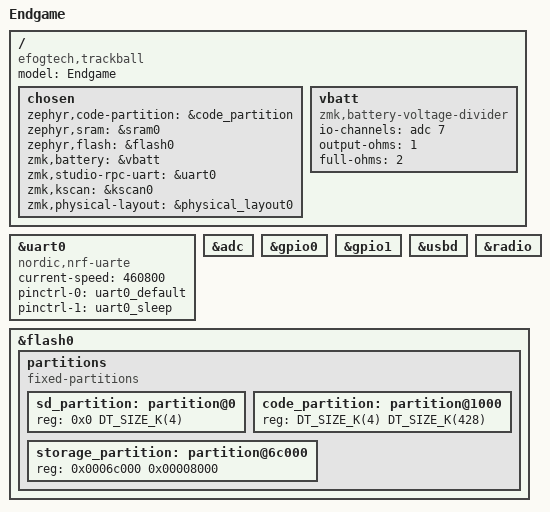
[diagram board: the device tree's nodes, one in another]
/dts-v1/;
#include <nordic/nrf52833_qiaa.dtsi>
#include <dt-bindings/zmk/input_transform.h>
#include <dt-bindings/zmk/matrix_transform.h>
#include <physical_layouts.dtsi>
#include <zephyr/dt-bindings/input/input-event-codes.h>
#include <input/processors.dtsi>
#include <dt-bindings/led/led.h>
#include "buttons.dtsi"
#include "behaviors_macros.dtsi"
#include "pinctrl.dtsi"
#include "pointer.dtsi"
#include "encoders.dtsi"
#include "visuals.dtsi"

/ {
    model = "Endgame";
    compatible = "efogtech,trackball";

    chosen {
        zephyr,code-partition = &code_partition;
        zephyr,sram = &sram0;
        zephyr,flash = &flash0;
        zmk,battery = &vbatt;
        zmk,studio-rpc-uart = &uart0;
        zmk,kscan = &kscan0;
        zmk,physical-layout = &physical_layout0;
    };

	vbatt: vbatt {
		compatible = "zmk,battery-voltage-divider";
		io-channels = <&adc 7>;
		output-ohms = <1>;
		full-ohms = <2>;
	};
};

&uart0 {
	compatible = "nordic,nrf-uarte";
	status = "okay";
	current-speed = <460800>;
	pinctrl-0 = <&uart0_default>;
	pinctrl-1 = <&uart0_sleep>;
	pinctrl-names = "default", "sleep";
};

&adc {
	status = "okay";
};

&gpio0 {
	status = "okay";
};

&gpio1 {
	status = "okay";
};

zephyr_udc0: &usbd {
    status = "okay";
};

&radio {
	status = "okay";
};

&flash0 {
    partitions {
        compatible = "fixed-partitions";
        #address-cells = <1>;
        #size-cells = <1>;

        sd_partition: partition@0 {
            reg = <0x0 DT_SIZE_K(4)>;
        };

        code_partition: partition@1000 {
            reg = <DT_SIZE_K(4) DT_SIZE_K(428)>;
        };

        storage_partition: partition@6c000 {
            reg = <0x0006c000 0x00008000>;
        };
    };
};
